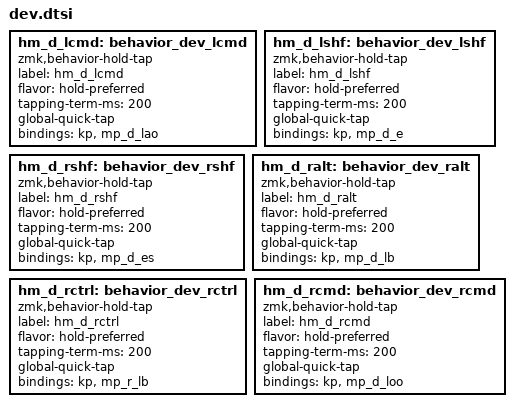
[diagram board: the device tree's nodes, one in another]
hm_d_lcmd: behavior_dev_lcmd {
    compatible = "zmk,behavior-hold-tap";
    label = "hm_d_lcmd";
    #binding-cells = <2>;
    flavor = "hold-preferred";
    tapping-term-ms = <200>;
    global-quick-tap;
    bindings = <&kp>, <&mp_d_lao>;
};

hm_d_lshf: behavior_dev_lshf {
    compatible = "zmk,behavior-hold-tap";
    label = "hm_d_lshf";
    #binding-cells = <2>;
    flavor = "hold-preferred";
    tapping-term-ms = <200>;
    global-quick-tap;
    bindings = <&kp>, <&mp_d_e>;
};

hm_d_rshf: behavior_dev_rshf {
    compatible = "zmk,behavior-hold-tap";
    label = "hm_d_rshf";
    #binding-cells = <2>;
    flavor = "hold-preferred";
    tapping-term-ms = <200>;
    global-quick-tap;
    bindings = <&kp>, <&mp_d_es>;
};

hm_d_ralt: behavior_dev_ralt {
    compatible = "zmk,behavior-hold-tap";
    label = "hm_d_ralt";
    #binding-cells = <2>;
    flavor = "hold-preferred";
    tapping-term-ms = <200>;
    global-quick-tap;
    bindings = <&kp>, <&mp_d_lb>;
};

hm_d_rctrl: behavior_dev_rctrl {
    compatible = "zmk,behavior-hold-tap";
    label = "hm_d_rctrl";
    #binding-cells = <2>;
    flavor = "hold-preferred";
    tapping-term-ms = <200>;
    global-quick-tap;
    bindings = <&kp>, <&mp_r_lb>;
};

hm_d_rcmd: behavior_dev_rcmd {
    compatible = "zmk,behavior-hold-tap";
    label = "hm_d_rcmd";
    #binding-cells = <2>;
    flavor = "hold-preferred";
    tapping-term-ms = <200>;
    global-quick-tap;
    bindings = <&kp>, <&mp_d_loo>;
};
